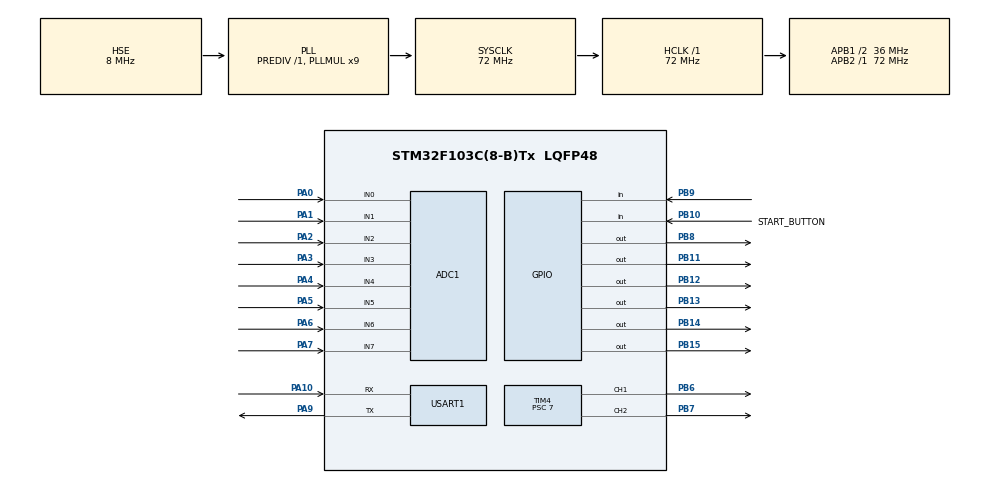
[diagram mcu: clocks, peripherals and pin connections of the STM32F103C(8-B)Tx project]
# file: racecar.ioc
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ADC1.Channel-0\#ChannelRegularConversion=ADC_CHANNEL_1
ADC1.NbrOfConversionFlag=1
ADC1.Rank-0\#ChannelRegularConversion=1
ADC1.SamplingTime-0\#ChannelRegularConversion=ADC_SAMPLETIME_55CYCLES_5
ADC1.master=1
Mcu.Family=STM32F1
Mcu.Name=STM32F103C(8-B)Tx
Mcu.Package=LQFP48
NVIC.PriorityGroup=NVIC_PRIORITYGROUP_4
NVIC.USART1_IRQn=true\:0\:0\:false\:false\:true\:true\:true\:true
PA0-WKUP.Signal=ADCx_IN0
PA1.Signal=ADCx_IN1
PA10.Mode=Asynchronous
PA10.Signal=USART1_RX
PA13.Mode=Serial_Wire
PA13.Signal=SYS_JTMS-SWDIO
PA14.Mode=Serial_Wire
PA14.Signal=SYS_JTCK-SWCLK
PA2.Signal=ADCx_IN2
PA3.Signal=ADCx_IN3
PA4.Signal=ADCx_IN4
PA5.Signal=ADCx_IN5
PA6.Signal=ADCx_IN6
PA7.Signal=ADCx_IN7
PA9.Mode=Asynchronous
PA9.Signal=USART1_TX
PB10.GPIO_Label=START_BUTTON
PB10.GPIO_PuPd=GPIO_PULLUP
PB10.Signal=GPIO_Input
PB11.Signal=GPIO_Output
PB12.Signal=GPIO_Output
PB13.Signal=GPIO_Output
PB14.Signal=GPIO_Output
PB15.Signal=GPIO_Output
PB6.Signal=S_TIM4_CH1
PB7.Signal=S_TIM4_CH2
PB8.Signal=GPIO_Output
PB9.Signal=GPIO_Input
PD0-OSC_IN.Mode=HSE-External-Oscillator
PD0-OSC_IN.Signal=RCC_OSC_IN
PD1-OSC_OUT.Mode=HSE-External-Oscillator
PD1-OSC_OUT.Signal=RCC_OSC_OUT
ProjectManager.HeapSize=0x200
ProjectManager.StackSize=0x400
ProjectManager.TargetToolchain=MDK-ARM V5.32
RCC.ADCPresc=RCC_ADCPCLK2_DIV6
RCC.AHBFreq_Value=72000000
RCC.APB1CLKDivider=RCC_HCLK_DIV2
RCC.APB1Freq_Value=36000000
RCC.APB1TimFreq_Value=72000000
RCC.APB2Freq_Value=72000000
RCC.APB2TimFreq_Value=72000000
RCC.HCLKFreq_Value=72000000
RCC.PLLMUL=RCC_PLL_MUL9
RCC.PLLSourceVirtual=RCC_PLLSOURCE_HSE
RCC.SYSCLKFreq_VALUE=72000000
RCC.SYSCLKSource=RCC_SYSCLKSOURCE_PLLCLK
RCC.USBFreq_Value=72000000
SH.ADCx_IN0.0=ADC1_IN0,IN0
SH.ADCx_IN1.0=ADC1_IN1,IN1
SH.ADCx_IN2.0=ADC1_IN2,IN2
SH.ADCx_IN3.0=ADC1_IN3,IN3
SH.ADCx_IN4.0=ADC1_IN4,IN4
SH.ADCx_IN5.0=ADC1_IN5,IN5
SH.ADCx_IN6.0=ADC1_IN6,IN6
SH.ADCx_IN7.0=ADC1_IN7,IN7
SH.S_TIM4_CH1.0=TIM4_CH1,PWM Generation1 CH1
SH.S_TIM4_CH2.0=TIM4_CH2,PWM Generation2 CH2
TIM4.Channel-PWM\ Generation1\ CH1=TIM_CHANNEL_1
TIM4.Channel-PWM\ Generation2\ CH2=TIM_CHANNEL_2
TIM4.Period=899
TIM4.Prescaler=7
USART1.VirtualMode=VM_ASYNC
board=custom

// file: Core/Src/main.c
/* USER CODE BEGIN Header */
/**
  ******************************************************************************
  * @file           : main.c
  * @brief          : Main program body
  ******************************************************************************
  * @attention
  *
  * Copyright (c) 2026 STMicroelectronics.
  * All rights reserved.
  *
  * This software is licensed under terms that can be found in the LICENSE file
  * in the root directory of this software component.
  * If no LICENSE file comes with this software, it is provided AS-IS.
  *
  ******************************************************************************
  */
/* USER CODE END Header */
#include "main.h"

/* USER CODE BEGIN Includes */
#include "app.h"
#include "motor.h"
/* USER CODE END Includes */

ADC_HandleTypeDef hadc1;

TIM_HandleTypeDef htim4;

UART_HandleTypeDef huart1;

void SystemClock_Config(void);
static void MX_GPIO_Init(void);
static void MX_ADC1_Init(void);
static void MX_TIM4_Init(void);
static void MX_USART1_UART_Init(void);
void App_Init(void);

int main(void)
{

  /* MCU Configuration--------------------------------------------------------*/

  /* Reset of all peripherals, Initializes the Flash interface and the Systick. */
  HAL_Init();

  /* Configure the system clock */
  SystemClock_Config();

  /* Initialize all configured peripherals */
  MX_GPIO_Init();
  MX_ADC1_Init();
  MX_TIM4_Init();
  MX_USART1_UART_Init();
  /* USER CODE BEGIN 2 */
  App_Init();
  /* USER CODE END 2 */

  /* Infinite loop */
  while (1)
  {
		 App_Loop();
  }
}

void SystemClock_Config(void)
{
  RCC_OscInitTypeDef RCC_OscInitStruct = {0};
  RCC_ClkInitTypeDef RCC_ClkInitStruct = {0};
  RCC_PeriphCLKInitTypeDef PeriphClkInit = {0};

  /** Initializes the RCC Oscillators according to the specified parameters
  * in the RCC_OscInitTypeDef structure.
  */
  RCC_OscInitStruct.OscillatorType = RCC_OSCILLATORTYPE_HSE;
  RCC_OscInitStruct.HSEState = RCC_HSE_ON;
  RCC_OscInitStruct.HSEPredivValue = RCC_HSE_PREDIV_DIV1;
  RCC_OscInitStruct.HSIState = RCC_HSI_ON;
  RCC_OscInitStruct.PLL.PLLState = RCC_PLL_ON;
  RCC_OscInitStruct.PLL.PLLSource = RCC_PLLSOURCE_HSE;
  RCC_OscInitStruct.PLL.PLLMUL = RCC_PLL_MUL9;
  if (HAL_RCC_OscConfig(&RCC_OscInitStruct) != HAL_OK)
  {
    Error_Handler();
  }

  /** Initializes the CPU, AHB and APB buses clocks
  */
  RCC_ClkInitStruct.ClockType = RCC_CLOCKTYPE_HCLK|RCC_CLOCKTYPE_SYSCLK
                              |RCC_CLOCKTYPE_PCLK1|RCC_CLOCKTYPE_PCLK2;
  RCC_ClkInitStruct.SYSCLKSource = RCC_SYSCLKSOURCE_PLLCLK;
  RCC_ClkInitStruct.AHBCLKDivider = RCC_SYSCLK_DIV1;
  RCC_ClkInitStruct.APB1CLKDivider = RCC_HCLK_DIV2;
  RCC_ClkInitStruct.APB2CLKDivider = RCC_HCLK_DIV1;

  if (HAL_RCC_ClockConfig(&RCC_ClkInitStruct, FLASH_LATENCY_2) != HAL_OK)
  {
    Error_Handler();
  }
  PeriphClkInit.PeriphClockSelection = RCC_PERIPHCLK_ADC;
  PeriphClkInit.AdcClockSelection = RCC_ADCPCLK2_DIV6;
  if (HAL_RCCEx_PeriphCLKConfig(&PeriphClkInit) != HAL_OK)
  {
    Error_Handler();
  }
}

static void MX_ADC1_Init(void)
{

  ADC_ChannelConfTypeDef sConfig = {0};

  /** Common config
  */
  hadc1.Instance = ADC1;
  hadc1.Init.ScanConvMode = ADC_SCAN_DISABLE;
  hadc1.Init.ContinuousConvMode = DISABLE;
  hadc1.Init.DiscontinuousConvMode = DISABLE;
  hadc1.Init.ExternalTrigConv = ADC_SOFTWARE_START;
  hadc1.Init.DataAlign = ADC_DATAALIGN_RIGHT;
  hadc1.Init.NbrOfConversion = 1;
  if (HAL_ADC_Init(&hadc1) != HAL_OK)
  {
    Error_Handler();
  }

  /** Configure Regular Channel
  */
  sConfig.Channel = ADC_CHANNEL_1;
  sConfig.Rank = ADC_REGULAR_RANK_1;
  sConfig.SamplingTime = ADC_SAMPLETIME_55CYCLES_5;
  if (HAL_ADC_ConfigChannel(&hadc1, &sConfig) != HAL_OK)
  {
    Error_Handler();
  }

}

static void MX_TIM4_Init(void)
{

  TIM_MasterConfigTypeDef sMasterConfig = {0};
  TIM_OC_InitTypeDef sConfigOC = {0};

  htim4.Instance = TIM4;
  htim4.Init.Prescaler = 7;
  htim4.Init.CounterMode = TIM_COUNTERMODE_UP;
  htim4.Init.Period = 899;
  htim4.Init.ClockDivision = TIM_CLOCKDIVISION_DIV1;
  htim4.Init.AutoReloadPreload = TIM_AUTORELOAD_PRELOAD_DISABLE;
  if (HAL_TIM_PWM_Init(&htim4) != HAL_OK)
  {
    Error_Handler();
  }
  sMasterConfig.MasterOutputTrigger = TIM_TRGO_RESET;
  sMasterConfig.MasterSlaveMode = TIM_MASTERSLAVEMODE_DISABLE;
  if (HAL_TIMEx_MasterConfigSynchronization(&htim4, &sMasterConfig) != HAL_OK)
  {
    Error_Handler();
  }
  sConfigOC.OCMode = TIM_OCMODE_PWM1;
  sConfigOC.Pulse = 0;
  sConfigOC.OCPolarity = TIM_OCPOLARITY_HIGH;
  sConfigOC.OCFastMode = TIM_OCFAST_DISABLE;
  if (HAL_TIM_PWM_ConfigChannel(&htim4, &sConfigOC, TIM_CHANNEL_1) != HAL_OK)
  {
    Error_Handler();
  }
  if (HAL_TIM_PWM_ConfigChannel(&htim4, &sConfigOC, TIM_CHANNEL_2) != HAL_OK)
  {
    Error_Handler();
  }
  HAL_TIM_MspPostInit(&htim4);

}

static void MX_USART1_UART_Init(void)
{

  huart1.Instance = USART1;
  huart1.Init.BaudRate = 115200;
  huart1.Init.WordLength = UART_WORDLENGTH_8B;
  huart1.Init.StopBits = UART_STOPBITS_1;
  huart1.Init.Parity = UART_PARITY_NONE;
  huart1.Init.Mode = UART_MODE_TX_RX;
  huart1.Init.HwFlowCtl = UART_HWCONTROL_NONE;
  huart1.Init.OverSampling = UART_OVERSAMPLING_16;
  if (HAL_UART_Init(&huart1) != HAL_OK)
  {
    Error_Handler();
  }

}

static void MX_GPIO_Init(void)
{
  GPIO_InitTypeDef GPIO_InitStruct = {0};

  /* GPIO Ports Clock Enable */
  __HAL_RCC_GPIOD_CLK_ENABLE();
  __HAL_RCC_GPIOA_CLK_ENABLE();
  __HAL_RCC_GPIOB_CLK_ENABLE();

  /*Configure GPIO pin Output Level */
  HAL_GPIO_WritePin(GPIOB, GPIO_PIN_11|GPIO_PIN_12|GPIO_PIN_13|GPIO_PIN_14
                          |GPIO_PIN_15|GPIO_PIN_8, GPIO_PIN_RESET);

  /*Configure GPIO pin : START_BUTTON_Pin */
  GPIO_InitStruct.Pin = START_BUTTON_Pin;
  GPIO_InitStruct.Mode = GPIO_MODE_INPUT;
  GPIO_InitStruct.Pull = GPIO_PULLUP;
  HAL_GPIO_Init(START_BUTTON_GPIO_Port, &GPIO_InitStruct);

  /*Configure GPIO pins : PB11 PB12 PB13 PB14
                           PB15 PB8 */
  GPIO_InitStruct.Pin = GPIO_PIN_11|GPIO_PIN_12|GPIO_PIN_13|GPIO_PIN_14
                          |GPIO_PIN_15|GPIO_PIN_8;
  GPIO_InitStruct.Mode = GPIO_MODE_OUTPUT_PP;
  GPIO_InitStruct.Pull = GPIO_NOPULL;
  GPIO_InitStruct.Speed = GPIO_SPEED_FREQ_LOW;
  HAL_GPIO_Init(GPIOB, &GPIO_InitStruct);

  /*Configure GPIO pin : PB9 */
  GPIO_InitStruct.Pin = GPIO_PIN_9;
  GPIO_InitStruct.Mode = GPIO_MODE_INPUT;
  GPIO_InitStruct.Pull = GPIO_NOPULL;
  HAL_GPIO_Init(GPIOB, &GPIO_InitStruct);

}

void Error_Handler(void)
{
  Motor_SafeOff();
  __disable_irq();
  while (1)
  {
  }
}
